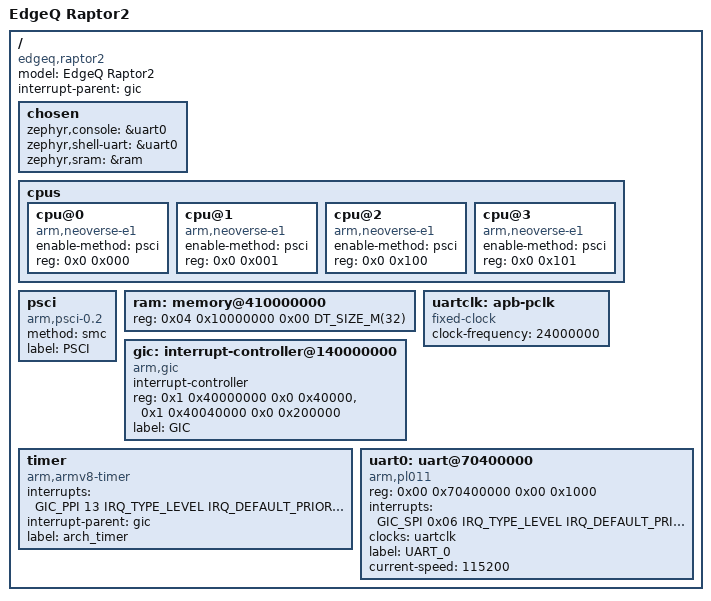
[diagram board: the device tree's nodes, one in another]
/*
 * Copyright 2021 EdgeQ Inc.
 *
 * SPDX-License-Identifier: Apache-2.0
 */

/dts-v1/;

#include <mem.h>
#include <dt-bindings/interrupt-controller/arm-gic.h>

/ {
	model = "EdgeQ Raptor2";
	compatible = "edgeq,raptor2";
	interrupt-parent = <&gic>;
	#address-cells = <0x02>;
	#size-cells = <0x02>;

	chosen {
		zephyr,console = &uart0;
		zephyr,shell-uart = &uart0;
		zephyr,sram = &ram;
	};

	cpus {
		#address-cells = <0x02>;
		#size-cells = <0x00>;

		cpu@0 {
			device_type = "cpu";
			compatible = "arm,neoverse-e1";
			enable-method = "psci";
			reg = <0x0 0x000>;
		};

		cpu@1 {
			device_type = "cpu";
			compatible = "arm,neoverse-e1";
			enable-method = "psci";
			reg = <0x0 0x001>;
		};

		cpu@2 {
			device_type = "cpu";
			compatible = "arm,neoverse-e1";
			enable-method = "psci";
			reg = <0x0 0x100>;
		};

		cpu@3 {
			device_type = "cpu";
			compatible = "arm,neoverse-e1";
			enable-method = "psci";
			reg = <0x0 0x101>;
		};
	};

	psci {
		compatible = "arm,psci-0.2";
		method = "smc";
		label = "PSCI";
	};

	ram: memory@410000000 {
		device_type = "mmio-sram";
		reg = <0x04 0x10000000 0x00 DT_SIZE_M(32)>;
	};

	gic: interrupt-controller@140000000 {
                compatible = "arm,gic";
                #interrupt-cells = <4>;
                #address-cells = <2>;
                #size-cells = <2>;
                ranges;
                interrupt-controller;
                reg =   <0x1 0x40000000 0x0 0x40000>,
                        <0x1 0x40040000 0x0 0x200000>;
		label = "GIC";
	};

	timer {
		compatible = "arm,armv8-timer";
		interrupts = <GIC_PPI 13 IRQ_TYPE_LEVEL IRQ_DEFAULT_PRIORITY
			      GIC_PPI 14 IRQ_TYPE_LEVEL IRQ_DEFAULT_PRIORITY
			      GIC_PPI 11 IRQ_TYPE_LEVEL IRQ_DEFAULT_PRIORITY
			      GIC_PPI 10 IRQ_TYPE_LEVEL IRQ_DEFAULT_PRIORITY>;
		interrupt-parent = <&gic>;
		label = "arch_timer";
	};

        uartclk: apb-pclk {
                compatible = "fixed-clock";
                clock-frequency = <24000000>;
                #clock-cells = <0>;
        };

	uart0: uart@70400000 {
		compatible = "arm,pl011";
		reg = <0x00 0x70400000 0x00 0x1000>;
		status = "okay";
		interrupt-names = "irq_0";
		interrupts = <GIC_SPI 0x06 IRQ_TYPE_LEVEL IRQ_DEFAULT_PRIORITY>;
		clocks = <&uartclk>;
		label = "UART_0";
		current-speed = <115200>;
       };

};
